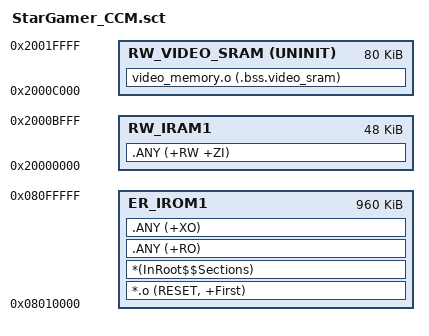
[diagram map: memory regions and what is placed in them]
; *************************************************************
; Star Gamer scatter file.
; *************************************************************

LR_IROM1 0x08010000 0x000F0000  {
  ER_IROM1 0x08010000 0x000F0000  {
   *.o (RESET, +First)
   *(InRoot$$Sections)
   .ANY (+RO)
   .ANY (+XO)
  }
  RW_IRAM1 0x20000000 0x0000C000  {
   .ANY (+RW +ZI)
  }
  RW_VIDEO_SRAM 0x2000C000 UNINIT 0x00014000  {
   video_memory.o (.bss.video_sram)
  }
}
